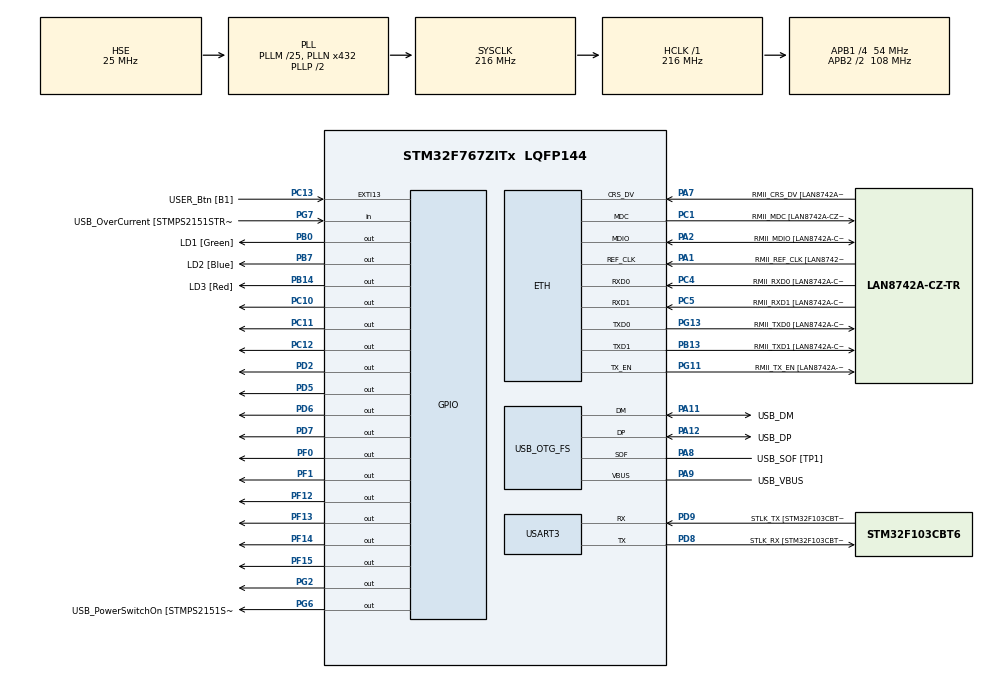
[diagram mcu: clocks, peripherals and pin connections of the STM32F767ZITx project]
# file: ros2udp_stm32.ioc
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ETH.MediaInterface=HAL_ETH_RMII_MODE
ETH.PHY_Name=LAN8742A_PHY_ADDRESS
ETH.PHY_Value=0
ETH.PhyAddress=0
ETH.RxMode=ETH_RXINTERRUPT_MODE
FREERTOS.Tasks01=defaultTask,24,256,StartDefaultTask,Default,NULL,Dynamic,NULL,NULL;udpReceiveTask,24,1024,StartTask02,Default,NULL,Dynamic,NULL,NULL
FREERTOS.configMINIMAL_STACK_SIZE=256
FREERTOS.configUSE_NEWLIB_REENTRANT=1
LWIP.BSP.number=1
LWIP.GATEWAY_ADDRESS=192.168.008.001
LWIP.IP_ADDRESS=192.168.008.215
LWIP.LWIP_DHCP=0
LWIP.NETMASK_ADDRESS=255.255.255.000
LWIP.Version=v2.1.2_Cube
LWIP0.BSP.STBoard=false
LWIP0.BSP.api=BSP_COMPONENT_DRIVER
LWIP0.BSP.component=LAN8742
LWIP0.BSP.instance=LAN8742
LWIP0.BSP.name=Driver_PHY
LWIP0.BSP.semaphore=S_LAN8742
LWIP0.BSP.solution=LAN8742
Mcu.Family=STM32F7
Mcu.Name=STM32F767ZITx
Mcu.Package=LQFP144
NVIC.ETH_IRQn=true\:5\:0\:false\:false\:true\:true\:false\:true\:true
NVIC.PriorityGroup=NVIC_PRIORITYGROUP_4
NVIC.TIM8_TRG_COM_TIM14_IRQn=true\:15\:0\:false\:false\:true\:false\:false\:true\:true
NVIC.TimeBase=TIM8_TRG_COM_TIM14_IRQn
NVIC.TimeBaseIP=TIM14
PA0/WKUP.Signal=S_TIM2_CH1_ETR
PA1.GPIO_Label=RMII_REF_CLK [LAN8742A-CZ-TR_REFCLK0]
PA1.Mode=RMII
PA1.Signal=ETH_REF_CLK
PA10.GPIO_Label=USB_ID
PA10.Signal=USB_OTG_FS_ID
PA11.GPIO_Label=USB_DM
PA11.Mode=Device_Only
PA11.Signal=USB_OTG_FS_DM
PA12.GPIO_Label=USB_DP
PA12.Mode=Device_Only
PA12.Signal=USB_OTG_FS_DP
PA13.GPIO_Label=TMS
PA13.Mode=Serial_Wire
PA13.Signal=SYS_JTMS-SWDIO
PA14.GPIO_Label=TCK
PA14.Mode=Serial_Wire
PA14.Signal=SYS_JTCK-SWCLK
PA2.GPIO_Label=RMII_MDIO [LAN8742A-CZ-TR_MDIO]
PA2.Mode=RMII
PA2.Signal=ETH_MDIO
PA3.Signal=S_TIM9_CH2
PA7.GPIO_Label=RMII_CRS_DV [LAN8742A-CZ-TR_CRS_DV]
PA7.Mode=RMII
PA7.Signal=ETH_CRS_DV
PA8.GPIO_Label=USB_SOF [TP1]
PA8.Mode=Activate_SOF_FS
PA8.Signal=USB_OTG_FS_SOF
PA9.GPIO_Label=USB_VBUS
PA9.Mode=Activate_VBUS
PA9.Signal=USB_OTG_FS_VBUS
PB0.GPIO_Label=LD1 [Green]
PB0.Signal=GPIO_Output
PB1.Signal=S_TIM3_CH4
PB13.GPIO_Label=RMII_TXD1 [LAN8742A-CZ-TR_TXD1]
PB13.Mode=RMII
PB13.Signal=ETH_TXD1
PB14.GPIO_Label=LD3 [Red]
PB14.Signal=GPIO_Output
PB3.GPIO_Label=SWO
PB3.Signal=SYS_JTDO-SWO
PB6.Signal=S_TIM4_CH1
PB7.GPIO_Label=LD2 [Blue]
PB7.Signal=GPIO_Output
PB8.Signal=S_TIM10_CH1
PC1.GPIO_Label=RMII_MDC [LAN8742A-CZ-TR_MDC]
PC1.Mode=RMII
PC1.Signal=ETH_MDC
PC10.Signal=GPIO_Output
PC11.Signal=GPIO_Output
PC12.Signal=GPIO_Output
PC13.GPIO_Label=USER_Btn [B1]
PC13.Signal=GPXTI13
PC14/OSC32_IN.Mode=LSE-External-Oscillator
PC14/OSC32_IN.Signal=RCC_OSC32_IN
PC15/OSC32_OUT.Mode=LSE-External-Oscillator
PC15/OSC32_OUT.Signal=RCC_OSC32_OUT
PC4.GPIO_Label=RMII_RXD0 [LAN8742A-CZ-TR_RXD0]
PC4.Mode=RMII
PC4.Signal=ETH_RXD0
PC5.GPIO_Label=RMII_RXD1 [LAN8742A-CZ-TR_RXD1]
PC5.Mode=RMII
PC5.Signal=ETH_RXD1
PC6.Signal=S_TIM3_CH1
PC7.Signal=S_TIM3_CH2
PC8.Signal=S_TIM8_CH3
PC9.Signal=S_TIM8_CH4
PD13.Signal=S_TIM4_CH2
PD2.Signal=GPIO_Output
PD5.Signal=GPIO_Output
PD6.Signal=GPIO_Output
PD7.Signal=GPIO_Output
PD8.GPIO_Label=STLK_RX [STM32F103CBT6_PA3]
PD8.Mode=Asynchronous
PD8.Signal=USART3_TX
PD9.GPIO_Label=STLK_TX [STM32F103CBT6_PA2]
PD9.Mode=Asynchronous
PD9.Signal=USART3_RX
PF0.Signal=GPIO_Output
PF1.Signal=GPIO_Output
PF12.Signal=GPIO_Output
PF13.Signal=GPIO_Output
PF14.Signal=GPIO_Output
PF15.Signal=GPIO_Output
PG11.GPIO_Label=RMII_TX_EN [LAN8742A-CZ-TR_TXEN]
PG11.Mode=RMII
PG11.Signal=ETH_TX_EN
PG13.GPIO_Label=RMII_TXD0 [LAN8742A-CZ-TR_TXD0]
PG13.Mode=RMII
PG13.Signal=ETH_TXD0
PG2.Signal=GPIO_Output
PG6.GPIO_Label=USB_PowerSwitchOn [STMPS2151STR_EN]
PG6.Signal=GPIO_Output
PG7.GPIO_Label=USB_OverCurrent [STMPS2151STR_FAULT]
PG7.Signal=GPIO_Input
PH0/OSC_IN.GPIO_Label=MCO [STM32F103CBT6_PA8]
PH0/OSC_IN.Mode=HSE-External-Clock-Source
PH0/OSC_IN.Signal=RCC_OSC_IN
PH1/OSC_OUT.Mode=HSE-External-Clock-Source
PH1/OSC_OUT.Signal=RCC_OSC_OUT
ProjectManager.HeapSize=0x200
ProjectManager.StackSize=0x400
ProjectManager.TargetToolchain=STM32CubeIDE
RCC.48MHZClocksFreq_Value=24000000
RCC.AHBFreq_Value=216000000
RCC.APB1CLKDivider=RCC_HCLK_DIV4
RCC.APB1Freq_Value=54000000
RCC.APB1TimFreq_Value=108000000
RCC.APB2CLKDivider=RCC_HCLK_DIV2
RCC.APB2Freq_Value=108000000
RCC.APB2TimFreq_Value=216000000
RCC.CortexFreq_Value=216000000
RCC.HCLKFreq_Value=216000000
RCC.HSE_VALUE=25000000
RCC.HSI_VALUE=16000000
RCC.PLLM=25
RCC.PLLMUL=RCC_PLL_MUL9
RCC.PLLN=432
RCC.PLLQ=9
RCC.PRESCALERUSB=RCC_USBCLKSOURCE_PLL_DIV1_5
RCC.SYSCLKFreq_VALUE=216000000
RCC.SYSCLKSource=RCC_SYSCLKSOURCE_PLLCLK
RCC.SYSCLKSourceVirtual=RCC_SYSCLKSOURCE_PLLCLK
RCC.USBFreq_Value=48000000
RCC.VCOOutputFreq_Value=432000000
SH.S_TIM10_CH1.0=TIM10_CH1
SH.S_TIM2_CH1_ETR.0=TIM2_CH1
SH.S_TIM3_CH1.0=TIM3_CH1
SH.S_TIM3_CH2.0=TIM3_CH2
SH.S_TIM3_CH4.0=TIM3_CH4
SH.S_TIM4_CH1.0=TIM4_CH1
SH.S_TIM4_CH2.0=TIM4_CH2
SH.S_TIM8_CH3.0=TIM8_CH3
SH.S_TIM8_CH4.0=TIM8_CH4
SH.S_TIM9_CH2.0=TIM9_CH2
USART3.VirtualMode-Asynchronous=VM_ASYNC
USB_OTG_FS.VirtualMode=Device_Only
VP_FREERTOS_VS_CMSIS_V2.Mode=CMSIS_V2
VP_LWIP_VS_Enabled.Mode=Enabled
VP_SYS_VS_tim14.Mode=TIM14
board=NUCLEO-F767ZI

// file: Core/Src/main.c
/* USER CODE BEGIN Header */
/**
  ******************************************************************************
  * @file           : main.c
  * @brief          : Main program body
  ******************************************************************************
  * @attention
  *
  * Copyright (c) 2025 STMicroelectronics.
  * All rights reserved.
  *
  * This software is licensed under terms that can be found in the LICENSE file
  * in the root directory of this software component.
  * If no LICENSE file comes with this software, it is provided AS-IS.
  *
  ******************************************************************************
  */
/* USER CODE END Header */
#include "main.h"
#include "cmsis_os.h"
#include "lwip.h"

/* USER CODE BEGIN Includes */
#include "udp_task.h"  // ここを追加
/* USER CODE END Includes */

UART_HandleTypeDef huart3;

PCD_HandleTypeDef hpcd_USB_OTG_FS;

/* Definitions for defaultTask */
osThreadId_t defaultTaskHandle;
const osThreadAttr_t defaultTask_attributes = {
  .name = "defaultTask",
  .stack_size = 256 * 4,
  .priority = (osPriority_t) osPriorityNormal,
};
/* Definitions for udpReceiveTask */
osThreadId_t udpReceiveTaskHandle;
const osThreadAttr_t udpReceiveTask_attributes = {
  .name = "udpReceiveTask",
  .stack_size = 1024 * 4,
  .priority = (osPriority_t) osPriorityNormal,
};

void SystemClock_Config(void);
static void MX_GPIO_Init(void);
static void MX_USART3_UART_Init(void);
static void MX_USB_OTG_FS_PCD_Init(void);
void StartDefaultTask(void *argument);
void StartTask02(void *argument);

int main(void)
{

  /* MCU Configuration--------------------------------------------------------*/

  /* Reset of all peripherals, Initializes the Flash interface and the Systick. */
  HAL_Init();

  /* Configure the system clock */
  SystemClock_Config();

  /* Initialize all configured peripherals */
  MX_GPIO_Init();
  MX_USART3_UART_Init();
  MX_USB_OTG_FS_PCD_Init();

  /* Init scheduler */
  osKernelInitialize();

  /* Create the thread(s) */
  /* creation of defaultTask */
  defaultTaskHandle = osThreadNew(StartDefaultTask, NULL, &defaultTask_attributes);

  /* creation of udpReceiveTask */
  udpReceiveTaskHandle = osThreadNew(StartTask02, NULL, &udpReceiveTask_attributes);

  /* Start scheduler */
  osKernelStart();

  /* We should never get here as control is now taken by the scheduler */

  /* Infinite loop */
  while (1)
  {

  }
}

void SystemClock_Config(void)
{
  RCC_OscInitTypeDef RCC_OscInitStruct = {0};
  RCC_ClkInitTypeDef RCC_ClkInitStruct = {0};

  /** Configure LSE Drive Capability
  */
  HAL_PWR_EnableBkUpAccess();

  /** Configure the main internal regulator output voltage
  */
  __HAL_RCC_PWR_CLK_ENABLE();
  __HAL_PWR_VOLTAGESCALING_CONFIG(PWR_REGULATOR_VOLTAGE_SCALE1);

  /** Initializes the RCC Oscillators according to the specified parameters
  * in the RCC_OscInitTypeDef structure.
  */
  RCC_OscInitStruct.OscillatorType = RCC_OSCILLATORTYPE_HSE;
  RCC_OscInitStruct.HSEState = RCC_HSE_BYPASS;
  RCC_OscInitStruct.PLL.PLLState = RCC_PLL_ON;
  RCC_OscInitStruct.PLL.PLLSource = RCC_PLLSOURCE_HSE;
  RCC_OscInitStruct.PLL.PLLM = 25;
  RCC_OscInitStruct.PLL.PLLN = 432;
  RCC_OscInitStruct.PLL.PLLP = RCC_PLLP_DIV2;
  RCC_OscInitStruct.PLL.PLLQ = 9;
  RCC_OscInitStruct.PLL.PLLR = 2;
  if (HAL_RCC_OscConfig(&RCC_OscInitStruct) != HAL_OK)
  {
    Error_Handler();
  }

  /** Activate the Over-Drive mode
  */
  if (HAL_PWREx_EnableOverDrive() != HAL_OK)
  {
    Error_Handler();
  }

  /** Initializes the CPU, AHB and APB buses clocks
  */
  RCC_ClkInitStruct.ClockType = RCC_CLOCKTYPE_HCLK|RCC_CLOCKTYPE_SYSCLK
                              |RCC_CLOCKTYPE_PCLK1|RCC_CLOCKTYPE_PCLK2;
  RCC_ClkInitStruct.SYSCLKSource = RCC_SYSCLKSOURCE_PLLCLK;
  RCC_ClkInitStruct.AHBCLKDivider = RCC_SYSCLK_DIV1;
  RCC_ClkInitStruct.APB1CLKDivider = RCC_HCLK_DIV4;
  RCC_ClkInitStruct.APB2CLKDivider = RCC_HCLK_DIV2;

  if (HAL_RCC_ClockConfig(&RCC_ClkInitStruct, FLASH_LATENCY_7) != HAL_OK)
  {
    Error_Handler();
  }
}

static void MX_USART3_UART_Init(void)
{

  huart3.Instance = USART3;
  huart3.Init.BaudRate = 115200;
  huart3.Init.WordLength = UART_WORDLENGTH_8B;
  huart3.Init.StopBits = UART_STOPBITS_1;
  huart3.Init.Parity = UART_PARITY_NONE;
  huart3.Init.Mode = UART_MODE_TX_RX;
  huart3.Init.HwFlowCtl = UART_HWCONTROL_NONE;
  huart3.Init.OverSampling = UART_OVERSAMPLING_16;
  huart3.Init.OneBitSampling = UART_ONE_BIT_SAMPLE_DISABLE;
  huart3.AdvancedInit.AdvFeatureInit = UART_ADVFEATURE_NO_INIT;
  if (HAL_UART_Init(&huart3) != HAL_OK)
  {
    Error_Handler();
  }

}

static void MX_USB_OTG_FS_PCD_Init(void)
{

  hpcd_USB_OTG_FS.Instance = USB_OTG_FS;
  hpcd_USB_OTG_FS.Init.dev_endpoints = 6;
  hpcd_USB_OTG_FS.Init.speed = PCD_SPEED_FULL;
  hpcd_USB_OTG_FS.Init.dma_enable = DISABLE;
  hpcd_USB_OTG_FS.Init.phy_itface = PCD_PHY_EMBEDDED;
  hpcd_USB_OTG_FS.Init.Sof_enable = ENABLE;
  hpcd_USB_OTG_FS.Init.low_power_enable = DISABLE;
  hpcd_USB_OTG_FS.Init.lpm_enable = DISABLE;
  hpcd_USB_OTG_FS.Init.vbus_sensing_enable = ENABLE;
  hpcd_USB_OTG_FS.Init.use_dedicated_ep1 = DISABLE;
  if (HAL_PCD_Init(&hpcd_USB_OTG_FS) != HAL_OK)
  {
    Error_Handler();
  }

}

static void MX_GPIO_Init(void)
{
  GPIO_InitTypeDef GPIO_InitStruct = {0};

  /* GPIO Ports Clock Enable */
  __HAL_RCC_GPIOC_CLK_ENABLE();
  __HAL_RCC_GPIOF_CLK_ENABLE();
  __HAL_RCC_GPIOH_CLK_ENABLE();
  __HAL_RCC_GPIOA_CLK_ENABLE();
  __HAL_RCC_GPIOB_CLK_ENABLE();
  __HAL_RCC_GPIOD_CLK_ENABLE();
  __HAL_RCC_GPIOG_CLK_ENABLE();

  /*Configure GPIO pin Output Level */
  HAL_GPIO_WritePin(GPIOF, GPIO_PIN_0|GPIO_PIN_1|GPIO_PIN_12|GPIO_PIN_13
                          |GPIO_PIN_14|GPIO_PIN_15, GPIO_PIN_RESET);

  /*Configure GPIO pin Output Level */
  HAL_GPIO_WritePin(GPIOB, LD1_Pin|LD3_Pin|LD2_Pin, GPIO_PIN_RESET);

  /*Configure GPIO pin Output Level */
  HAL_GPIO_WritePin(GPIOG, GPIO_PIN_2|USB_PowerSwitchOn_Pin, GPIO_PIN_RESET);

  /*Configure GPIO pin Output Level */
  HAL_GPIO_WritePin(GPIOC, GPIO_PIN_10|GPIO_PIN_11|GPIO_PIN_12, GPIO_PIN_RESET);

  /*Configure GPIO pin Output Level */
  HAL_GPIO_WritePin(GPIOD, GPIO_PIN_2|GPIO_PIN_5|GPIO_PIN_6|GPIO_PIN_7, GPIO_PIN_RESET);

  /*Configure GPIO pin : USER_Btn_Pin */
  GPIO_InitStruct.Pin = USER_Btn_Pin;
  GPIO_InitStruct.Mode = GPIO_MODE_IT_RISING;
  GPIO_InitStruct.Pull = GPIO_NOPULL;
  HAL_GPIO_Init(USER_Btn_GPIO_Port, &GPIO_InitStruct);

  /*Configure GPIO pins : PF0 PF1 PF12 PF13
                           PF14 PF15 */
  GPIO_InitStruct.Pin = GPIO_PIN_0|GPIO_PIN_1|GPIO_PIN_12|GPIO_PIN_13
                          |GPIO_PIN_14|GPIO_PIN_15;
  GPIO_InitStruct.Mode = GPIO_MODE_OUTPUT_PP;
  GPIO_InitStruct.Pull = GPIO_NOPULL;
  GPIO_InitStruct.Speed = GPIO_SPEED_FREQ_LOW;
  HAL_GPIO_Init(GPIOF, &GPIO_InitStruct);

  /*Configure GPIO pin : PA0 */
  GPIO_InitStruct.Pin = GPIO_PIN_0;
  GPIO_InitStruct.Mode = GPIO_MODE_AF_PP;
  GPIO_InitStruct.Pull = GPIO_NOPULL;
  GPIO_InitStruct.Speed = GPIO_SPEED_FREQ_LOW;
  GPIO_InitStruct.Alternate = GPIO_AF1_TIM2;
  HAL_GPIO_Init(GPIOA, &GPIO_InitStruct);

  /*Configure GPIO pin : PA3 */
  GPIO_InitStruct.Pin = GPIO_PIN_3;
  GPIO_InitStruct.Mode = GPIO_MODE_AF_PP;
  GPIO_InitStruct.Pull = GPIO_NOPULL;
  GPIO_InitStruct.Speed = GPIO_SPEED_FREQ_LOW;
  GPIO_InitStruct.Alternate = GPIO_AF3_TIM9;
  HAL_GPIO_Init(GPIOA, &GPIO_InitStruct);

  /*Configure GPIO pins : LD1_Pin LD3_Pin LD2_Pin */
  GPIO_InitStruct.Pin = LD1_Pin|LD3_Pin|LD2_Pin;
  GPIO_InitStruct.Mode = GPIO_MODE_OUTPUT_PP;
  GPIO_InitStruct.Pull = GPIO_NOPULL;
  GPIO_InitStruct.Speed = GPIO_SPEED_FREQ_LOW;
  HAL_GPIO_Init(GPIOB, &GPIO_InitStruct);

  /*Configure GPIO pin : PB1 */
  GPIO_InitStruct.Pin = GPIO_PIN_1;
  GPIO_InitStruct.Mode = GPIO_MODE_AF_PP;
  GPIO_InitStruct.Pull = GPIO_NOPULL;
  GPIO_InitStruct.Speed = GPIO_SPEED_FREQ_LOW;
  GPIO_InitStruct.Alternate = GPIO_AF2_TIM3;
  HAL_GPIO_Init(GPIOB, &GPIO_InitStruct);

  /*Configure GPIO pin : PD13 */
  GPIO_InitStruct.Pin = GPIO_PIN_13;
  GPIO_InitStruct.Mode = GPIO_MODE_AF_PP;
  GPIO_InitStruct.Pull = GPIO_NOPULL;
  GPIO_InitStruct.Speed = GPIO_SPEED_FREQ_LOW;
  GPIO_InitStruct.Alternate = GPIO_AF2_TIM4;
  HAL_GPIO_Init(GPIOD, &GPIO_InitStruct);

  /*Configure GPIO pins : PG2 USB_PowerSwitchOn_Pin */
  GPIO_InitStruct.Pin = GPIO_PIN_2|USB_PowerSwitchOn_Pin;
  GPIO_InitStruct.Mode = GPIO_MODE_OUTPUT_PP;
  GPIO_InitStruct.Pull = GPIO_NOPULL;
  GPIO_InitStruct.Speed = GPIO_SPEED_FREQ_LOW;
  HAL_GPIO_Init(GPIOG, &GPIO_InitStruct);

  /*Configure GPIO pin : USB_OverCurrent_Pin */
  GPIO_InitStruct.Pin = USB_OverCurrent_Pin;
  GPIO_InitStruct.Mode = GPIO_MODE_INPUT;
  GPIO_InitStruct.Pull = GPIO_NOPULL;
  HAL_GPIO_Init(USB_OverCurrent_GPIO_Port, &GPIO_InitStruct);

  /*Configure GPIO pins : PC6 PC7 */
  GPIO_InitStruct.Pin = GPIO_PIN_6|GPIO_PIN_7;
  GPIO_InitStruct.Mode = GPIO_MODE_AF_PP;
  GPIO_InitStruct.Pull = GPIO_NOPULL;
  GPIO_InitStruct.Speed = GPIO_SPEED_FREQ_LOW;
  GPIO_InitStruct.Alternate = GPIO_AF2_TIM3;
  HAL_GPIO_Init(GPIOC, &GPIO_InitStruct);

  /*Configure GPIO pins : PC8 PC9 */
  GPIO_InitStruct.Pin = GPIO_PIN_8|GPIO_PIN_9;
  GPIO_InitStruct.Mode = GPIO_MODE_AF_PP;
  GPIO_InitStruct.Pull = GPIO_NOPULL;
  GPIO_InitStruct.Speed = GPIO_SPEED_FREQ_LOW;
  GPIO_InitStruct.Alternate = GPIO_AF3_TIM8;
  HAL_GPIO_Init(GPIOC, &GPIO_InitStruct);

  /*Configure GPIO pins : PC10 PC11 PC12 */
  GPIO_InitStruct.Pin = GPIO_PIN_10|GPIO_PIN_11|GPIO_PIN_12;
  GPIO_InitStruct.Mode = GPIO_MODE_OUTPUT_PP;
  GPIO_InitStruct.Pull = GPIO_NOPULL;
  GPIO_InitStruct.Speed = GPIO_SPEED_FREQ_LOW;
  HAL_GPIO_Init(GPIOC, &GPIO_InitStruct);

  /*Configure GPIO pins : PD2 PD5 PD6 PD7 */
  GPIO_InitStruct.Pin = GPIO_PIN_2|GPIO_PIN_5|GPIO_PIN_6|GPIO_PIN_7;
  GPIO_InitStruct.Mode = GPIO_MODE_OUTPUT_PP;
  GPIO_InitStruct.Pull = GPIO_NOPULL;
  GPIO_InitStruct.Speed = GPIO_SPEED_FREQ_LOW;
  HAL_GPIO_Init(GPIOD, &GPIO_InitStruct);

  /*Configure GPIO pin : PB6 */
  GPIO_InitStruct.Pin = GPIO_PIN_6;
  GPIO_InitStruct.Mode = GPIO_MODE_AF_PP;
  GPIO_InitStruct.Pull = GPIO_NOPULL;
  GPIO_InitStruct.Speed = GPIO_SPEED_FREQ_LOW;
  GPIO_InitStruct.Alternate = GPIO_AF2_TIM4;
  HAL_GPIO_Init(GPIOB, &GPIO_InitStruct);

  /*Configure GPIO pin : PB8 */
  GPIO_InitStruct.Pin = GPIO_PIN_8;
  GPIO_InitStruct.Mode = GPIO_MODE_AF_PP;
  GPIO_InitStruct.Pull = GPIO_NOPULL;
  GPIO_InitStruct.Speed = GPIO_SPEED_FREQ_LOW;
  GPIO_InitStruct.Alternate = GPIO_AF3_TIM10;
  HAL_GPIO_Init(GPIOB, &GPIO_InitStruct);

}

void StartDefaultTask(void *argument)
{
  /* init code for LWIP */
  MX_LWIP_Init();
  for(;;)
  {
    osDelay(1);
  }
}

void StartTask02(void *argument)
{
  for(;;)
  {
    osDelay(1);
  }
}

void HAL_TIM_PeriodElapsedCallback(TIM_HandleTypeDef *htim)
{
  if (htim->Instance == TIM14) {
    HAL_IncTick();
  }
}

void Error_Handler(void)
{
  __disable_irq();
  while (1)
  {
  }
}
